# nrf54h20_engb_sysctrl register map
Vendor: Nordic Semiconductor; Series: nRF54h; File version: 1
Registers are 32-bit, read-write, reset 0x0 unless marked. A register's access mark holds for its fields unless they carry their own. Offsets are from the block's base; [hi:lo] are bit positions; lines under a group give offsets from that group; 'fields as' and 'values as' point back to an identical list.

## LFXO — LFXO peripheral
Base 0x5F953000
0x100 EVENTS_MODECHANGED — LFXO mode changed
  [0] EVENTS_MODECHANGED
    0=NotGenerated (Event not generated); 1=Generated (Event generated)
0x104 EVENTS_ERRORSTARTING — Error while starting the LFXO in PIERCE mode
  [0] EVENTS_ERRORSTARTING
    values as EVENTS_MODECHANGED.EVENTS_MODECHANGED
0x108 EVENTS_ERRORRUNNING — Error detected while LFXO was running
  [0] EVENTS_ERRORRUNNING
    values as EVENTS_MODECHANGED.EVENTS_MODECHANGED
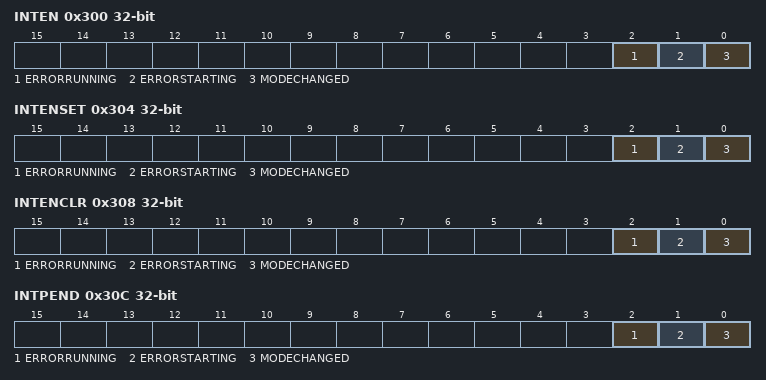
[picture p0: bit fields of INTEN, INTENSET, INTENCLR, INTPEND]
0x300 INTEN — Enable or disable interrupt
  [all] fields
    0=Disabled; 1=Enabled
  [2] ERRORRUNNING — Enable or disable interrupt for event ERRORRUNNING
  [1] ERRORSTARTING — Enable or disable interrupt for event ERRORSTARTING
  [0] MODECHANGED — Enable or disable interrupt for event MODECHANGED
0x304 INTENSET — Enable interrupt
  [all] fields
    on read: 0=Disabled (Read: Disabled); 1=Enabled (Read: Enabled) | on write: 1=Set (Enable)
  [2] ERRORRUNNING — Write '1' to enable interrupt for event ERRORRUNNING
  [1] ERRORSTARTING — Write '1' to enable interrupt for event ERRORSTARTING
  [0] MODECHANGED — Write '1' to enable interrupt for event MODECHANGED
0x308 INTENCLR — Disable interrupt
  [all] fields
    on read: 0=Disabled (Read: Disabled); 1=Enabled (Read: Enabled) | on write: 1=Clear (Disable)
  [2] ERRORRUNNING — Write '1' to disable interrupt for event ERRORRUNNING
  [1] ERRORSTARTING — Write '1' to disable interrupt for event ERRORSTARTING
  [0] MODECHANGED — Write '1' to disable interrupt for event MODECHANGED
0x30C INTPEND ro — Pending interrupts
  [all] fields
    on read: 0=NotPending (Read: Not pending); 1=Pending (Read: Pending)
  [2] ERRORRUNNING — Read pending status of interrupt for event ERRORRUNNING
  [1] ERRORSTARTING — Read pending status of interrupt for event ERRORSTARTING
  [0] MODECHANGED — Read pending status of interrupt for event MODECHANGED
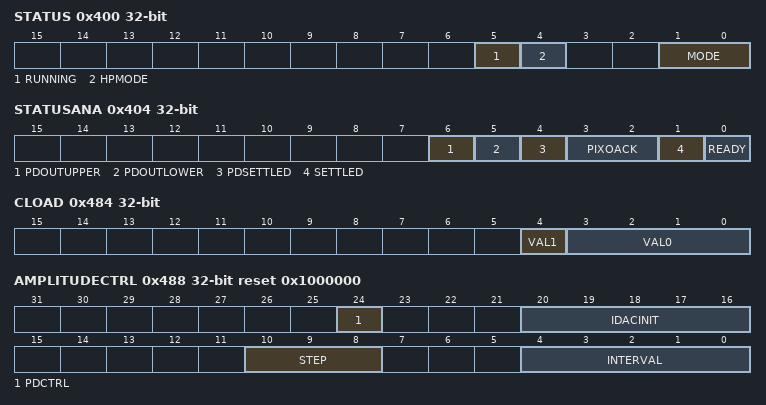
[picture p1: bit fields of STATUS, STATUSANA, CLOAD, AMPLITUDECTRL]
0x400 STATUS ro — LFXO status
  [5] RUNNING — LFXO running status
    0=NotRunning (LFXO not running); 1=Running (LFXO running)
  [4] HPMODE — High performance mode
    0=Disabled (High performance mode disabled); 1=Enabled (High performance mode enabled)
  [1:0] MODE — Current mode
    0=Pierce mode; 1=PIXO mode; 2=External sine wave clock; 3=External square wave clock
0x404 STATUSANA ro — Status of analog module output signals
  [6] PDOUTUPPER — Current value of the PD_OUT_UPPER signal from the analog module
  [5] PDOUTLOWER — Current value of the PD_OUT_LOWER signal from the analog module
  [4] PDSETTLED — Current value of the PD_SETTLED signal from the analog module
  [3:2] PIXOACK — Current value of the PIXO_ACK signal from the analog module
  [1] SETTLED — Current value of the SETTLED signal from the analog module
  [0] READY — Current value of the READY signal from the analog module
0x440 TRIM group — Unspecified
  0x00 PDLOWERTHR — Peak detector lower threshold trim
    [4:0] VAL — Peak detector lower threshold trimming value
  0x04 PDUPPERTHR — Peak detector upper threshold trim
    [4:0] VAL — Peak detector upper threshold trimming value
  0x08 BIAS — Internal bias generator trim
    [3:0] VAL
  0x0C PIXO — PIXO high pulse supply trim
    [4:0] VAL
  0x10 TRIMBUS — Reserved trim bus
    [2:0] VAL — Value
0x480 MIRROR reset 0x1 — Enable LOCK for mirrored registers
  [0] LOCK — Lock for mirrored registers
    0=Disabled (Lock disabled); 1=Enabled (Lock enabled)
0x484 CLOAD — Internal capacitive load
  [4] VAL1 — Capacitive load value
  [3:0] VAL0 — Capacitive load value
0x488 AMPLITUDECTRL reset 0x1000000 — Amplitude control
  [24] PDCTRL — Peak detector control
    0=Disabled (Peak detector disabled); 1=Enabled (Peak detector enabled)
  [20:16] IDACINIT — Initial IDAC code for the pierce oscillator
  [10:8] STEP — Step to adjust the IDAC when the peak detector triggers
  [4:0] INTERVAL — Amplitude check interval
0x48C PWRUPCTRL — Power up control
  [1:0] CTRL
    0=Automatically handled by the peripheral; 1=PowerUp; 2=PowerDown
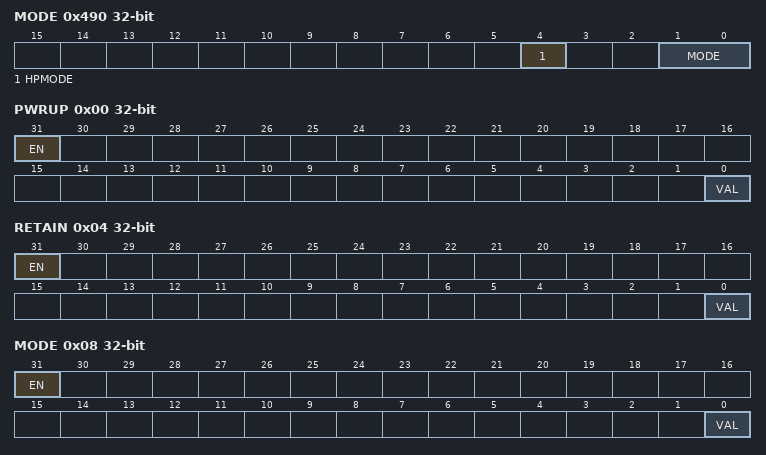
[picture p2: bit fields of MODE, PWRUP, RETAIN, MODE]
0x490 MODE — LFXO mode
  [4] HPMODE — High performance mode
    0=Disabled (Disable high performance mode); 1=Enabled (Enable high performance mode)
  [1:0] MODE
    values as STATUS.MODE
0x500 OVERRIDE group — Unspecified
  0x00 PWRUP — Override the PWRUP signal to the analog module
    [31] EN — Enable the override
      0=Disabled (Override is disabled); 1=Enabled (Override is enabled)
    [0] VAL — Override value for the signal
  0x04 RETAIN — Override the RETAIN signal to the analog module
    fields as OVERRIDE.PWRUP
  0x08 MODE — Override the MODE signal to the analog module
    [31] EN — Enable the override
      values as OVERRIDE.PWRUP.EN
    [0] VAL — Value
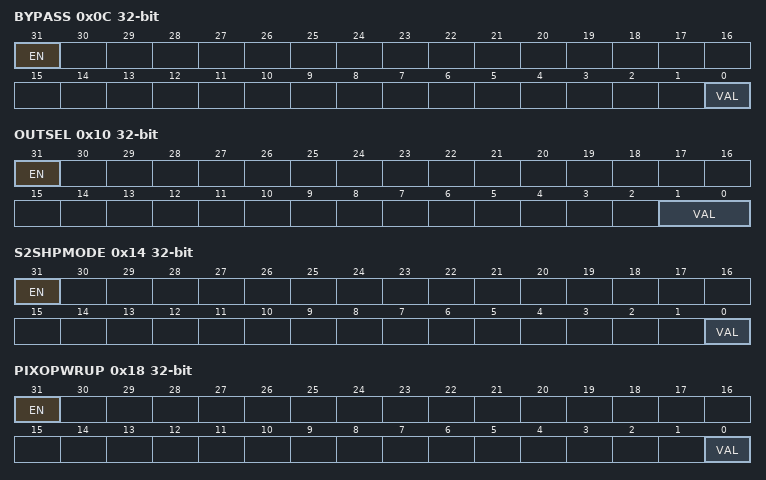
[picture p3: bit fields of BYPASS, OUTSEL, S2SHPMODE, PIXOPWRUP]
  0x0C BYPASS — Override the BYPASS signal to the analog module
    fields as OVERRIDE.MODE
  0x10 OUTSEL — Override the OUTSEL[1:0] signal to the analog module
    [31] EN — Enable the override
      values as OVERRIDE.PWRUP.EN
    [1:0] VAL — Value
  0x14 S2SHPMODE — Override the S2S_HPMODE signal to the analog module
    fields as OVERRIDE.MODE
  0x18 PIXOPWRUP — Override the PIXO_PWRUP signal to the analog module
    fields as OVERRIDE.MODE
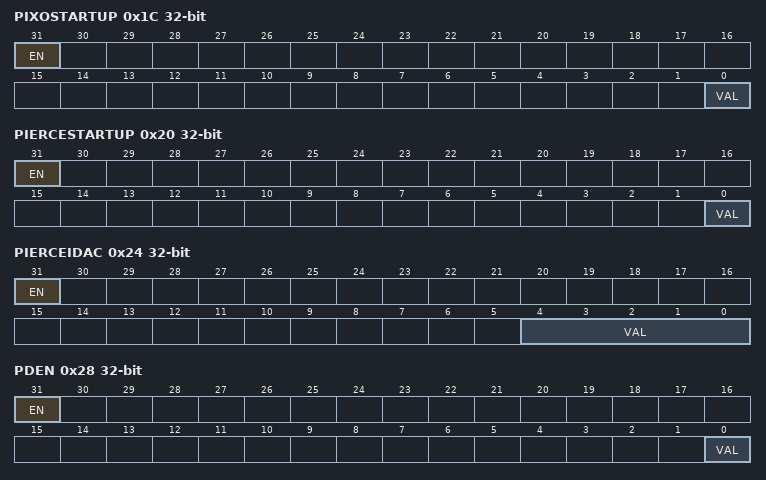
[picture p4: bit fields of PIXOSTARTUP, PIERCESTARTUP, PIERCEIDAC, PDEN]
  0x1C PIXOSTARTUP — Override the PIXO_STARTUP signal to the analog module
    fields as OVERRIDE.MODE
  0x20 PIERCESTARTUP — Override the PIERCE_STARTUP signal to the analog module
    fields as OVERRIDE.MODE
  0x24 PIERCEIDAC — Override the PIERCE_IDAC signal to the analog module
    [31] EN — Enable the override
      values as OVERRIDE.PWRUP.EN
    [4:0] VAL — Value
  0x28 PDEN — Override the PD_EN signal to the analog module
    fields as OVERRIDE.MODE
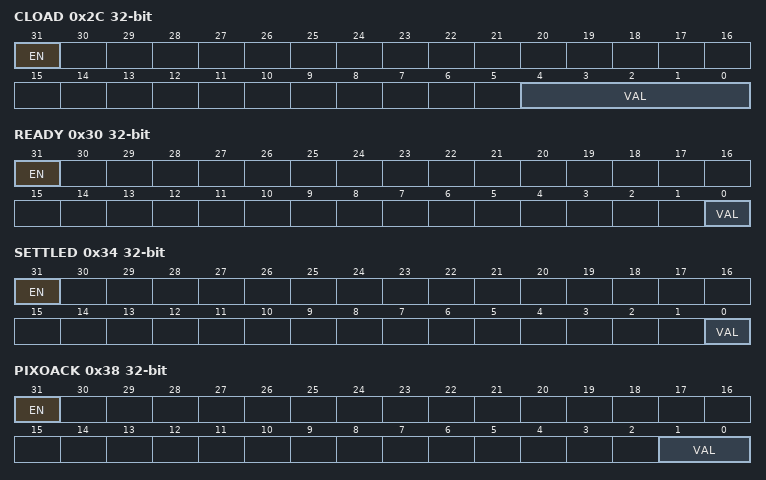
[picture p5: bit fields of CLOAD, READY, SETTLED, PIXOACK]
  0x2C CLOAD — Override the CLOAD signal to the analog module
    fields as OVERRIDE.PIERCEIDAC
  0x30 READY — Override the READY signal from the analog module
    [31] EN — Enable the override
      values as OVERRIDE.PWRUP.EN
    [0] VAL — Current value of the signal
  0x34 SETTLED — Override the SETTLED signal from the analog module
    fields as OVERRIDE.READY
  0x38 PIXOACK — Override the PIXO_ACK signal from the analog module
    [31] EN — Enable the override
      values as OVERRIDE.PWRUP.EN
    [1:0] VAL — Current value of the signal
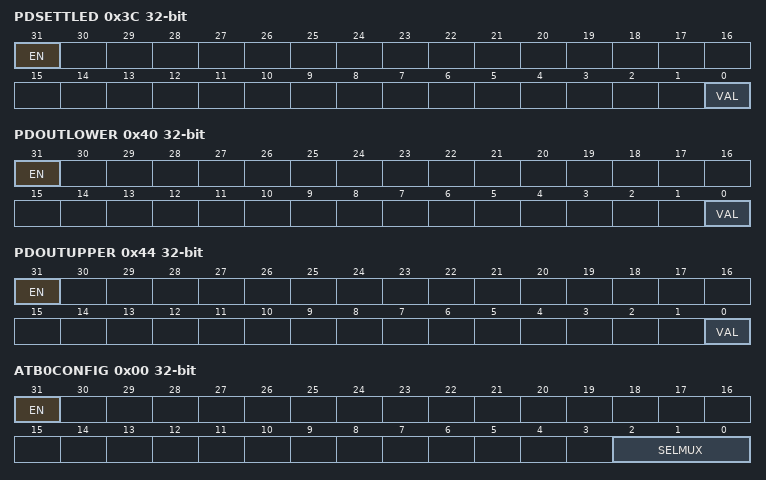
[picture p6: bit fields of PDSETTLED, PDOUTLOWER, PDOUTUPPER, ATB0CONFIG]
  0x3C PDSETTLED — Override the PD_SETTLED signal from the analog module
    fields as OVERRIDE.READY
  0x40 PDOUTLOWER — Override the PD_OUT_LOWER signal from the analog module
    fields as OVERRIDE.READY
  0x44 PDOUTUPPER — Override the PD_OUT_UPPER signal from the analog module
    fields as OVERRIDE.READY
0x600 DFT group — Unspecified
  0x00 ATB0CONFIG — Analog Test Bus 0 (ATB0) configuration
    [31] EN — Enable the analog test bus
      0=Disabled (Analog test bus is disabled(HiZ)); 1=Enabled (Analog test bus is enabled)
    [2:0] SELMUX — Select multiplexer for ATB0
      0=XC1 (Functional tests/main production test); 1=XC2 (Test/trim peak detector); 2=ITEST (Test/trim current generator (or possibly IDAC).); 4=VDDINT0V8 (Measure current consumption VDD_INT_0V8.); 5=VDDINT1V8 (Measure current consumption VDD_INT_1V8.)
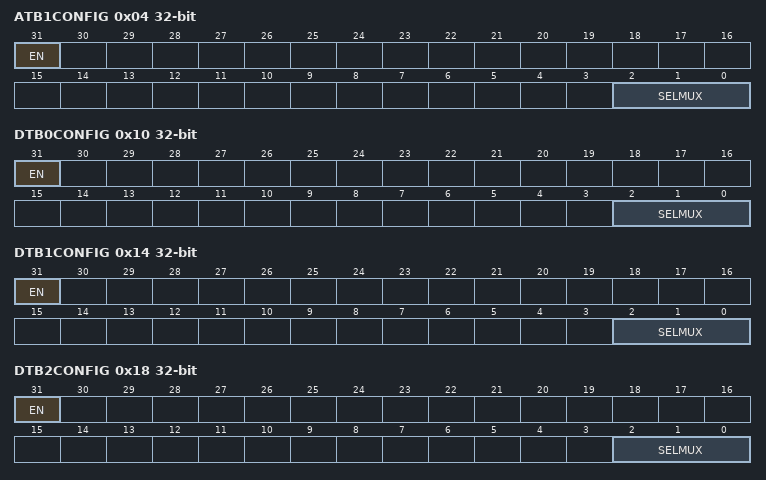
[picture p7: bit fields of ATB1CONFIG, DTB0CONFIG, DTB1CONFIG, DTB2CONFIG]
  0x04 ATB1CONFIG — Analog Test Bus 1 (ATB1) configuration
    [31] EN — Enable the analog test bus
      values as DFT.ATB0CONFIG.EN
    [2:0] SELMUX — Select multiplexer for ATB1
      0=XC2 (Functional tests/main production test); 1=VPIU (Test/trim upper PIXO supply); 4=VDDINT0V8 (Measure current consumption VDD_INT_0V8.); 5=VDDINT1V8 (Measure current consumption VDD_INT_1V8.)
  0x10 DTB0CONFIG — Digital Test Bus 0 (DTB0) configuration
    [31] EN — Enable the digital test bus
      0=Disabled (Digital test bus is disabled); 1=Enabled (Digital test bus is enabled)
    [2:0] SELMUX — Select multiplexer for DTB0
      0=OSC32K; 1=PDLOWER; 2=PIXOPULSENEG; 3=PIXOACK0; 4=IDAC3 (Observe IDAC[3].); 5=IDAC0 (Observe IDAC[0].)
  0x14 DTB1CONFIG — Digital Test Bus 1 (DTB1) configuration
    [31] EN — Enable the digital test bus
      values as DFT.DTB0CONFIG.EN
    [2:0] SELMUX — Select multiplexer for DTB1
      0=READY; 1=PDUPPER; 2=PIXOPULSEPOS; 3=PIXOACK1; 4=IDAC4 (Observe IDAC[4].); 5=IDAC1 (Observe IDAC[1].)
  0x18 DTB2CONFIG — Digital Test Bus 2 (DTB2) configuration
    [31] EN — Enable the digital test bus
      values as DFT.DTB0CONFIG.EN
    [2:0] SELMUX — Select multiplexer for DTB2
      0=SETTLED; 4=PIERCESTARTUP; 5=IDAC2 (Observe IDAC[2].)
  0x1C DTB3CONFIG — Digital Test Bus 3 (DTB3) configuration
    [27] PWRUPDELTEST — Enable the PWRUP delay test circuit
      0=Disabled (PWRUP delay test circuit is disabled); 1=Enabled (PWRUP delay test circuit is enabled)
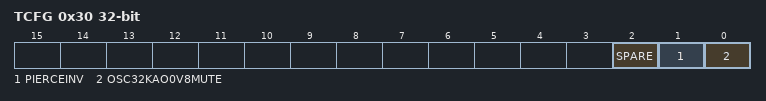
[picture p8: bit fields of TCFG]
  0x30 TCFG — Test mode configuration
    [2] SPARE — Spare bit
    [1] PIERCEINV — Disable PIERCE inverter
      0=Enabled (Pierce inverter enabled); 1=Disabled (Pierce inverter disabled)
    [0] OSC32KAO0V8MUTE — OSC_32K_AO_0V8 muted
      0=Disabled (Override disabled); 1=Enabled (Override enabled)
